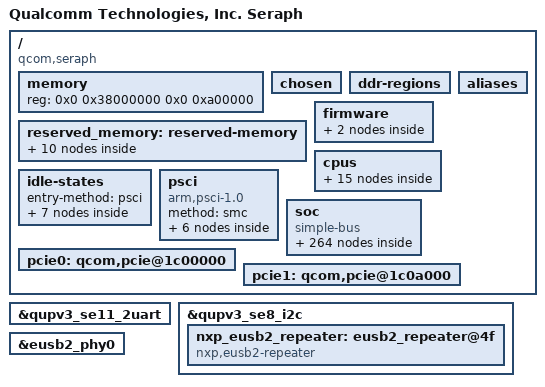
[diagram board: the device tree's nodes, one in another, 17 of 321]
// SPDX-License-Identifier: BSD-3-Clause
/*
 * Copyright (c) Qualcomm Technologies, Inc. and/or its subsidiaries.
 */

#include <dt-bindings/arm/msm/qti-smmu-proxy-dt-ids.h>
#include <dt-bindings/interrupt-controller/arm-gic.h>
#include <dt-bindings/soc/qcom,rpmh-rsc.h>
#include <dt-bindings/clock/qcom,rpmh.h>
#include <dt-bindings/clock/qcom,camcc-seraph.h>
#include <dt-bindings/clock/qcom,evacc-seraph.h>
#include <dt-bindings/clock/qcom,gcc-seraph.h>
#include <dt-bindings/clock/qcom,gpucc-seraph.h>
#include <dt-bindings/clock/qcom,lsrcc-seraph.h>
#include <dt-bindings/clock/qcom,tcsrcc-seraph.h>
#include <dt-bindings/clock/qcom,videocc-seraph.h>
#include <dt-bindings/interconnect/qcom,seraph.h>
#include <dt-bindings/soc/qcom,ipcc.h>
#include <dt-bindings/power/qcom-aoss-qmp.h>
#include <dt-bindings/clock/qcom,aop-qmp.h>
#include <dt-bindings/spmi/spmi.h>
#include <dt-bindings/regulator/qcom,rpmh-regulator-levels.h>
#include <dt-bindings/interrupt-controller/irq.h>
#include <dt-bindings/mailbox/qcom-ipcc.h>

/ {
	model = "Qualcomm Technologies, Inc. Seraph";
	compatible = "qcom,seraph";
	qcom,msm-id = <672 0x10000>;
	interrupt-parent = <&intc>;

	#address-cells = <2>;
	#size-cells = <2>;
	memory { device_type = "memory"; reg = <0x0 0x38000000 0x0 0xa00000>; };

	chosen: chosen {
		bootargs = "loglevel=6 log_buf_len=256K bootconfig swiotlb=0 kasan=off cgroup_disable=pressure cgroup.memory=nokmem,nosocket disable_dma32=on restrict_cma_redirect=false pci=pcie_bus_safe,noaer pcie_pme=nomsi printk.console_no_auto_verbose=1 rcupdate.rcu_expedited=1 rcu_nocbs=0-4 kernel.panic_on_rcu_stall=1 no-steal-acc ftrace_dump_on_oops can.stats_timer=0 fw_devlink.strict=1 service_locator.enable=1 firmware_class.path=/vendor/firmware_mnt/image,/vendor/firmware irqaffinity=0-1 loop.max_part=7 cpufreq.default_governor=performance android_arch_task_struct_size=512 no-steal-acc pci-msm-drv.pcie_sm_regs=0x1D07000,0x1040,0x1048,0x3000,0x2 net.ifnames=0 hibernate.compressor=lz4";
	};

	reserved_memory: reserved-memory {};
	ddr-regions { };

	aliases: aliases {
		serial0 = &qupv3_se11_2uart;
		hsuart0 = &qupv3_se7_4uart;
		hsuart1 = &qupv3_se3_2uart;
		hsuart2 = &qupv3_se1_1uart;
		i2c0 = &qupv3_se0_i2c;
		i2c1 = &qupv3_se1_i2c;
		i2c2 = &qupv3_se2_i2c;
		i2c3 = &qupv3_se3_i2c;
		i2c4 = &qupv3_se4_i2c;
		i2c5 = &qupv3_se5_i2c;
		i2c6 = &qupv3_se6_i2c;
		i2c8 = &qupv3_se8_i2c;
		i2c9 = &qupv3_se9_i2c;
		i2c10 = &qupv3_se10_i2c;
		mmc0 = &sdhc_1;
		spi0 = &qupv3_se0_spi;
		spi1 = &qupv3_se1_spi;
		spi2 = &qupv3_se2_spi;
		spi3 = &qupv3_se3_spi;
		spi4 = &qupv3_se4_spi;
		spi5 = &qupv3_se5_spi;
		spi6 = &qupv3_se6_spi;
		spi8 = &qupv3_se8_spi;
		spi9 = &qupv3_se9_spi;
		spi10 = &qupv3_se10_spi;
	};

	firmware: firmware {
		qcom_scm: qcom_scm { };
	};

	cpus {
		#address-cells = <2>;
		#size-cells = <0>;

		CPU0: cpu@0 {
			device_type = "cpu";
			compatible = "qcom,kryo";
			reg = <0x0 0x0>;
			enable-method = "psci";
			cpu-idle-states = <&SILVER_OFF &SILVER_RAIL_OFF>;
			power-domains = <&CPU_PD0>;
			power-domain-names = "psci";
			next-level-cache = <&L2_0>;
			qcom,freq-domain = <&cpufreq_hw 0>;
			capacity-dmips-mhz = <1024>;
			dynamic-power-coefficient = <100>;
			#cooling-cells = <2>;
			L2_0: l2-cache {
				compatible = "arm,arch-cache";
				cache-level = <2>;
				next-level-cache = <&L3_0>;

				L3_0: l3-cache {
					compatible = "arm,arch-cache";
					cache-level = <3>;
				};
			};
		};

		CPU1: cpu@100 {
			device_type = "cpu";
			compatible = "qcom,kryo";
			reg = <0x0 0x100>;
			enable-method = "psci";
			cpu-idle-states = <&SILVER_OFF &SILVER_RAIL_OFF>;
			power-domains = <&CPU_PD1>;
			power-domain-names = "psci";
			next-level-cache = <&L2_0>;
			qcom,freq-domain = <&cpufreq_hw 0>;
			capacity-dmips-mhz = <1024>;
			dynamic-power-coefficient = <100>;
			#cooling-cells = <2>;
		};

		CPU2: cpu@200 {
			device_type = "cpu";
			compatible = "qcom,kryo";
			reg = <0x0 0x200>;
			enable-method = "psci";
			cpu-idle-states = <&SILVER_OFF &SILVER_RAIL_OFF>;
			power-domains = <&CPU_PD2>;
			power-domain-names = "psci";
			next-level-cache = <&L2_0>;
			qcom,freq-domain = <&cpufreq_hw 0>;
			capacity-dmips-mhz = <1024>;
			dynamic-power-coefficient = <100>;
			#cooling-cells = <2>;
		};

		CPU3: cpu@300 {
			device_type = "cpu";
			compatible = "qcom,kryo";
			reg = <0x0 0x300>;
			enable-method = "psci";
			cpu-idle-states = <&SILVER_OFF &SILVER_RAIL_OFF>;
			power-domains = <&CPU_PD3>;
			power-domain-names = "psci";
			next-level-cache = <&L2_0>;
			qcom,freq-domain = <&cpufreq_hw 0>;
			capacity-dmips-mhz = <1024>;
			dynamic-power-coefficient = <100>;
			#cooling-cells = <2>;
		};

		CPU4: cpu@400 {
			device_type = "cpu";
			compatible = "qcom,kryo";
			reg = <0x0 0x400>;
			enable-method = "psci";
			cpu-idle-states = <&GOLD_OFF &GOLD_RAIL_OFF>;
			power-domains = <&CPU_PD4>;
			power-domain-names = "psci";
			next-level-cache = <&L2_0>;
			qcom,freq-domain = <&cpufreq_hw 1>;
			capacity-dmips-mhz = <1956>;
			dynamic-power-coefficient = <389>;
			#cooling-cells = <2>;
		};

		cpu-map {
			cluster0 {
				core0 {
					cpu = <&CPU0>;
				};

				core1 {
					cpu = <&CPU1>;
				};

				core2 {
					cpu = <&CPU2>;
				};

				core3 {
					cpu = <&CPU3>;
				};
			};

			cluster1 {
				core0 {
					cpu = <&CPU4>;
				};
			};
		};
	};

	idle-states {
		entry-method = "psci";

		SILVER_OFF: silver-c3 {  /* C3 */
			compatible = "arm,idle-state";
			idle-state-name = "pc";
			entry-latency-us = <161>;
			exit-latency-us = <274>;
			min-residency-us = <3200>;
			arm,psci-suspend-param = <0x40000003>;
			local-timer-stop;
		};

		SILVER_RAIL_OFF: silver-cluster0-c4 { /* C4 */
			compatible = "arm,idle-state";
			idle-state-name = "rail-pc";
			entry-latency-us = <292>;
			exit-latency-us = <368>;
			min-residency-us = <6700>;
			arm,psci-suspend-param = <0x40000004>;
			local-timer-stop;
		};

		GOLD_OFF: gold-c3 {  /* C3 */
			compatible = "arm,idle-state";
			idle-state-name = "pc";
			entry-latency-us = <164>;
			exit-latency-us = <457>;
			min-residency-us = <4011>;
			arm,psci-suspend-param = <0x40000003>;
			local-timer-stop;
		};

		GOLD_RAIL_OFF: gold-cluster1-c4 { /* C4 */
			compatible = "arm,idle-state";
			idle-state-name = "rail-pc";
			entry-latency-us = <220>;
			exit-latency-us = <541>;
			min-residency-us = <7951>;
			arm,psci-suspend-param = <0x40000004>;
			local-timer-stop;
		};

		CLUSTER_PWR_DN: cluster-d4 { /* D4 */
			compatible = "domain-idle-state";
			idle-state-name = "l3-off";
			entry-latency-us = <429>;
			exit-latency-us = <1259>;
			min-residency-us = <9144>;
			arm,psci-suspend-param = <0x41000044>;
		};

		CX_OFF: cx-off { /* Cx Off */
			compatible = "domain-idle-state";
			idle-state-name = "cx-ret";
			entry-latency-us = <539>;
			exit-latency-us = <1571>;
			min-residency-us = <8550>;
			arm,psci-suspend-param = <0x41002344>;
		};

		APSS_OFF: cluster-e3 { /* E3 */
			compatible = "domain-idle-state";
			idle-state-name = "llcc-off";
			entry-latency-us = <540>;
			exit-latency-us = <1569>;
			min-residency-us = <10150>;
			arm,psci-suspend-param = <0x4100c344>;
		};
	};

	psci {
		compatible = "arm,psci-1.0";
		method = "smc";

		CPU_PD0: cpu-pd0 {
			#power-domain-cells = <0>;
			power-domains = <&CLUSTER_PD>;
		};

		CPU_PD1: cpu-pd1 {
			#power-domain-cells = <0>;
			power-domains = <&CLUSTER_PD>;
		};

		CPU_PD2: cpu-pd2 {
			#power-domain-cells = <0>;
			power-domains = <&CLUSTER_PD>;
		};

		CPU_PD3: cpu-pd3 {
			#power-domain-cells = <0>;
			power-domains = <&CLUSTER_PD>;
		};

		CPU_PD4: cpu-pd4 {
			#power-domain-cells = <0>;
			power-domains = <&CLUSTER_PD>;
		};

		CLUSTER_PD: cluster-pd {
			#power-domain-cells = <0>;
			domain-idle-states = <&CLUSTER_PWR_DN &CX_OFF &APSS_OFF>;
		};
	};

	soc: soc { };

	pcie0: qcom,pcie@1c00000 { };

	pcie1: qcom,pcie@1c0a000 { };
};

&soc {
	#address-cells = <1>;
	#size-cells = <1>;

	ranges = <0 0 0 0xffffffff>;
	compatible = "simple-bus";

	disp_rdump_region@d5100000 {
	};

	qcom,qrtr-gunyah-tuivm {
		compatible = "qcom,qrtr-gunyah";
		qcom,master;
		gunyah-label = <0x103>;
		peer-name = <2>;
	};

	msm_gpu: qcom,kgsl-3d0@3d00000 { };

	kryo-erp {
		compatible = "arm,arm64-kryo-cpu-erp";
		interrupts = <GIC_PPI 6 IRQ_TYPE_LEVEL_HIGH>,
			     <GIC_SPI 35 IRQ_TYPE_LEVEL_HIGH>;
		interrupt-names = "l1-l2-faultirq","l3-scu-faultirq";
	};

	cluster-device {
		compatible = "qcom,lpm-cluster-dev";
		power-domains = <&CLUSTER_PD>;
	};

	intc: interrupt-controller@17200000 {
		compatible = "arm,gic-v3";
		#interrupt-cells = <3>;
		interrupt-controller;
		ranges;
		#redistributor-regions = <1>;
		redistributor-stride = <0x0 0x20000>;
		reg = <0x17200000 0x10000>,       /* GICD */
		     <0x17260000 0xA0000>;       /* GICR * 5 */
		interrupts = <GIC_PPI 9 IRQ_TYPE_LEVEL_HIGH>;

		gic_its: msi-controller@17240000 {
			compatible = "arm,gic-v3-its";
			msi-controller;
			#msi-cells = <1>;
			reg = <0x17240000 0x20000>;
		};
	};

	arch_timer: timer {
		compatible = "arm,armv8-timer";
		interrupts = <GIC_PPI 13 (GIC_CPU_MASK_SIMPLE(8) | IRQ_TYPE_LEVEL_LOW)>,
			     <GIC_PPI 14 (GIC_CPU_MASK_SIMPLE(8) | IRQ_TYPE_LEVEL_LOW)>,
			     <GIC_PPI 11 (GIC_CPU_MASK_SIMPLE(8) | IRQ_TYPE_LEVEL_LOW)>,
			     <GIC_PPI 12 (GIC_CPU_MASK_SIMPLE(8) | IRQ_TYPE_LEVEL_LOW)>;
		clock-frequency = <19200000>;
	};

	show_resume_irqs@0x17200000 {
		compatible = "qcom,show-resume-irqs";
		reg = <0x17200000 0x110000>;
	};

	ipcc_mproc: qcom,ipcc@404000 {
		compatible = "qcom,ipcc";
		reg = <0x404000 0x1000>;
		interrupts = <GIC_SPI 229 IRQ_TYPE_LEVEL_HIGH>;
		interrupt-controller;
		#interrupt-cells = <3>;
		#mbox-cells = <2>;
	};

	aoss_qmp: power-controller@c300000 {
		compatible = "qcom,aoss-qmp";
		reg = <0xc300000 0x400>;
		interrupt-parent = <&ipcc_mproc>;
		interrupts = <IPCC_CLIENT_AOP
			      IPCC_MPROC_SIGNAL_GLINK_QMP
			      IRQ_TYPE_EDGE_RISING>;
		mboxes = <&ipcc_mproc IPCC_CLIENT_AOP
			  IPCC_MPROC_SIGNAL_GLINK_QMP>;

		#power-domain-cells = <1>;
		#clock-cells = <0>;
	};

	qmp_tme: qcom,qmp-tme {
		compatible = "qcom,qmp-mbox";
		qcom,remote-pid = <14>;
		mboxes = <&ipcc_mproc IPCC_CLIENT_TME
			  IPCC_MPROC_SIGNAL_GLINK_QMP>;
		mbox-names = "tme_qmp";
		interrupt-parent = <&ipcc_mproc>;
		interrupts = <IPCC_CLIENT_TME
			      IPCC_MPROC_SIGNAL_GLINK_QMP
			      IRQ_TYPE_EDGE_RISING>;

		label = "tme";
		qcom,early-boot;
		priority = <0>;
		mbox-desc-offset = <0x0>;
		#mbox-cells = <1>;
	};

	qcom,glink {
		compatible = "qcom,glink";
	};

	qmp_aop: qcom,qmp-aop {
		compatible = "qcom,qmp-mbox";
		qcom,qmp = <&aoss_qmp>;
		label = "aop";
		#mbox-cells = <1>;
	};

	tcsr_mutex_block: syscon@1f40000 {
		compatible = "syscon";
		reg = <0x1f40000 0x20000>;
	};

	tcsr_mutex: hwlock {
		compatible = "qcom,tcsr-mutex";
		syscon = <&tcsr_mutex_block 0 0x1000>;
		#hwlock-cells = <1>;
	};

	tcsr: syscon@1f40000 {
		compatible = "syscon";
		reg = <0x1f40000 0xc0000>;
	};

	qcom,smp2p-adsp {
		compatible = "qcom,smp2p";
		qcom,smem = <443>, <429>;
		interrupt-parent = <&ipcc_mproc>;
		interrupts = <IPCC_CLIENT_LPASS IPCC_MPROC_SIGNAL_SMP2P
			      IRQ_TYPE_EDGE_RISING>;
		mboxes = <&ipcc_mproc IPCC_CLIENT_LPASS
			  IPCC_MPROC_SIGNAL_SMP2P>;
		qcom,local-pid = <0>;
		qcom,remote-pid = <2>;

		adsp_smp2p_out: master-kernel {
			qcom,entry-name = "master-kernel";
			#qcom,smem-state-cells = <1>;
		};

		adsp_smp2p_in: slave-kernel {
			qcom,entry-name = "slave-kernel";
			interrupt-controller;
			#interrupt-cells = <2>;
		};

		sleepstate_smp2p_out: sleepstate-out {
			qcom,entry-name = "sleepstate";
			#qcom,smem-state-cells = <1>;
		};

		sleepstate_smp2p_in: qcom,sleepstate-in {
			qcom,entry-name = "sleepstate_see";
			interrupt-controller;
			#interrupt-cells = <2>;
		};

		smp2p_rdbg2_out: qcom,smp2p-rdbg2-out {
			qcom,entry-name = "rdbg";
			#qcom,smem-state-cells = <1>;
		};

		smp2p_rdbg2_in: qcom,smp2p-rdbg2-in {
			qcom,entry-name = "rdbg";
			interrupt-controller;
			#interrupt-cells = <2>;
		};
	};

	qcom,smp2p-cdsp {
		compatible = "qcom,smp2p";
		qcom,smem = <94>, <432>;
		interrupt-parent = <&ipcc_mproc>;
		interrupts = <IPCC_CLIENT_CDSP IPCC_MPROC_SIGNAL_SMP2P
			      IRQ_TYPE_EDGE_RISING>;
		mboxes = <&ipcc_mproc IPCC_CLIENT_CDSP IPCC_MPROC_SIGNAL_SMP2P>;
		qcom,local-pid = <0>;
		qcom,remote-pid = <5>;

		cdsp_smp2p_out: master-kernel {
			qcom,entry-name = "master-kernel";
			#qcom,smem-state-cells = <1>;
		};

		cdsp_smp2p_in: slave-kernel {
			qcom,entry-name = "slave-kernel";
			interrupt-controller;
			#interrupt-cells = <2>;
		};

		smp2p_rdbg5_out: qcom,smp2p-rdbg5-out {
			qcom,entry-name = "rdbg";
			#qcom,smem-state-cells = <1>;
		};

		smp2p_rdbg5_in: qcom,smp2p-rdbg5-in {
			qcom,entry-name = "rdbg";
			interrupt-controller;
			#interrupt-cells = <2>;
		};
	};

	qcom,smp2p-soccp {
		compatible = "qcom,smp2p";
		qcom,smem = <617>, <616>;
		interrupt-parent = <&ipcc_mproc>;
		interrupts = <IPCC_CLIENT_SOCCP IPCC_MPROC_SIGNAL_SMP2P
			      IRQ_TYPE_EDGE_RISING>;
		mboxes = <&ipcc_mproc IPCC_CLIENT_SOCCP IPCC_MPROC_SIGNAL_SMP2P>;
		qcom,local-pid = <0>;
		qcom,remote-pid = <19>;

		soccp_smp2p_out: master-kernel {
			qcom,entry-name = "master-kernel";
			#qcom,smem-state-cells = <1>;
		};

		soccp_smp2p_in: slave-kernel {
			qcom,entry-name = "slave-kernel";
			interrupt-controller;
			#interrupt-cells = <2>;
		};
	};

	qcom_smp2p_dcp: qcom,smp2p-dcp {
		compatible = "qcom,smp2p";
		qcom,smem = <617>, <616>;
		interrupt-parent = <&ipcc_mproc>;
		interrupts = <IPCC_CLIENT_DCP IPCC_MPROC_SIGNAL_SMP2P
			      IRQ_TYPE_EDGE_RISING>;
		mboxes = <&ipcc_mproc IPCC_CLIENT_DCP IPCC_MPROC_SIGNAL_SMP2P>;
		qcom,local-pid = <0>;
		qcom,remote-pid = <22>;

		dcp_smp2p_out: master-kernel {
			qcom,entry-name = "master-kernel";
			#qcom,smem-state-cells = <1>;
		};

		dcp_smp2p_in: slave-kernel {
			qcom,entry-name = "slave-kernel";
			interrupt-controller;
			#interrupt-cells = <2>;
		};
	};

	qcom,smp2p_sleepstate {
		compatible = "qcom,smp2p-sleepstate";
		qcom,smem-states = <&sleepstate_smp2p_out 0>;
		interrupt-parent = <&sleepstate_smp2p_in>;
		interrupts = <0 0>;
		interrupt-names = "smp2p-sleepstate-in";
	};

	qcom,glinkpkt {
		compatible = "qcom,glinkpkt";

		qcom,glinkpkt-at-mdm0 {
			qcom,glinkpkt-edge = "mpss";
			qcom,glinkpkt-ch-name = "DS";
			qcom,glinkpkt-dev-name = "at_mdm0";
		};

		qcom,glinkpkt-ctrl-cdsp {
			qcom,glinkpkt-edge = "cdsp";
			qcom,glinkpkt-ch-name = "LOOPBACK_CTL_CDSP";
			qcom,glinkpkt-dev-name = "glink_pkt_ctrl_cdsp";
		};

		qcom,glinkpkt-data-cdsp {
			qcom,glinkpkt-edge = "cdsp";
			qcom,glinkpkt-ch-name = "LOOPBACK_DATA_CDSP";
			qcom,glinkpkt-dev-name = "glink_pkt_data_cdsp";
		};

		qcom,glinkpkt-ctrl-lpass {
			qcom,glinkpkt-edge = "lpass";
			qcom,glinkpkt-ch-name = "LOOPBACK_CTL_LPASS";
			qcom,glinkpkt-dev-name = "glink_pkt_ctrl_lpass";
		};

		qcom,glinkpkt-data-lpass {
			qcom,glinkpkt-edge = "lpass";
			qcom,glinkpkt-ch-name = "LOOPBACK_DATA_LPASS";
			qcom,glinkpkt-dev-name = "glink_pkt_data_lpass";
		};

		qcom,glinkpkt-ctrl-mpss {
			qcom,glinkpkt-edge = "mpss";
			qcom,glinkpkt-ch-name = "LOOPBACK_CTL_MPSS";
			qcom,glinkpkt-dev-name = "glink_pkt_ctrl_mpss";
		};

		qcom,glinkpkt-data-mpss {
			qcom,glinkpkt-edge = "mpss";
			qcom,glinkpkt-ch-name = "LOOPBACK_DATA_MPSS";
			qcom,glinkpkt-dev-name = "glink_pkt_data_mpss";
		};

		qcom,glinkpkt-apr-apps2 {
			qcom,glinkpkt-edge = "adsp";
			qcom,glinkpkt-ch-name = "apr_apps2";
			qcom,glinkpkt-dev-name = "apr_apps2";
		};

		qcom,glinkpkt-data40-cntl {
			qcom,glinkpkt-edge = "mpss";
			qcom,glinkpkt-ch-name = "DATA40_CNTL";
			qcom,glinkpkt-dev-name = "smdcntl8";
		};

		qcom,glinkpkt-data1 {
			qcom,glinkpkt-edge = "mpss";
			qcom,glinkpkt-ch-name = "DATA1";
			qcom,glinkpkt-dev-name = "smd7";
		};

		qcom,glinkpkt-data4 {
			qcom,glinkpkt-edge = "mpss";
			qcom,glinkpkt-ch-name = "DATA4";
			qcom,glinkpkt-dev-name = "smd8";
		};

		qcom,glinkpkt-data11 {
			qcom,glinkpkt-edge = "mpss";
			qcom,glinkpkt-ch-name = "DATA11";
			qcom,glinkpkt-dev-name = "smd11";
		};

		qcom,glinkpkt-qmc-dma {
			qcom,glinkpkt-edge = "mpss";
			qcom,glinkpkt-ch-name = "QMC_DMA_LINE";
			qcom,glinkpkt-dev-name = "qmc_dma";
			qcom,glinkpkt-enable-ch-close;
		};

		qcom,glinkpkt-qmc-cma {
			qcom,glinkpkt-edge = "mpss";
			qcom,glinkpkt-ch-name = "QMC_CMA_LINE";
			qcom,glinkpkt-dev-name = "qmc_cma";
			qcom,glinkpkt-enable-ch-close;
		};

		qcom,glinkpkt-ims-sub-1 {
			qcom,glinkpkt-edge = "mpss";
			qcom,glinkpkt-ch-name = "Ims_dc_sub1";
			qcom,glinkpkt-dev-name = "ims_dc_sub1";
			qcom,glinkpkt-enable-ch-close;
		};

		qcom,glinkpkt-ims-sub-2 {
			qcom,glinkpkt-edge = "mpss";
			qcom,glinkpkt-ch-name = "Ims_dc_sub2";
			qcom,glinkpkt-dev-name = "ims_dc_sub2";
			qcom,glinkpkt-enable-ch-close;
		};

		qcom,glinkpkt-xpan_control {
			qcom,glinkpkt-edge = "adsp";
			qcom,glinkpkt-ch-name = "bt_cp_ctrl";
			qcom,glinkpkt-dev-name = "bt_cp_ctrl";
		};

		qcom,glinkpkt-hci-aribter {
			qcom,glinkpkt-edge = "lpass";
			qcom,glinkpkt-ch-name = "hci_arbiter_chnl";
			qcom,glinkpkt-dev-name = "glink_pkt_hci_arbiter_chnl";
			qcom,glinkpkt-enable-ch-close;
		};

		qcom,glinkpkt-socket-offload {
			qcom,glinkpkt-edge = "lpass";
			qcom,glinkpkt-ch-name = "bt_socket_hal_chnl";
			qcom,glinkpkt-dev-name = "glink_pkt_bt_socket_hal_chnl";
			qcom,glinkpkt-enable-ch-close;
		};

		qcom,glinkpkt-gatt-offload {
			qcom,glinkpkt-edge = "lpass";
			qcom,glinkpkt-ch-name = "gatt_offload_chnl";
			qcom,glinkpkt-dev-name = "glink_pkt_bt_gatt_offload_chnl";
			qcom,glinkpkt-enable-ch-close;
		};
	};

	memtimer: timer@17420000 {
		#address-cells = <1>;
		#size-cells = <1>;
		ranges;
		compatible = "arm,armv7-timer-mem";
		reg = <0x17420000 0x1000>;
		clock-frequency = <19200000>;

		frame@17421000 {
			frame-number = <0>;
			interrupts = <GIC_SPI 8 IRQ_TYPE_LEVEL_HIGH>,
				     <GIC_SPI 6 IRQ_TYPE_LEVEL_HIGH>;
			reg = <0x17421000 0x1000>,
			      <0x17422000 0x1000>;
		};

		frame@17423000 {
			frame-number = <1>;
			interrupts = <GIC_SPI 9 IRQ_TYPE_LEVEL_HIGH>;
			reg = <0x17423000 0x1000>;
			status = "disabled";
		};

		frame@17425000 {
			frame-number = <2>;
			interrupts = <GIC_SPI 10 IRQ_TYPE_LEVEL_HIGH>;
			reg = <0x17425000 0x1000>;
			status = "disabled";
		};

		frame@17427000 {
			frame-number = <3>;
			interrupts = <GIC_SPI 11 IRQ_TYPE_LEVEL_HIGH>;
			reg = <0x17427000 0x1000>;
			status = "disabled";
		};

		frame@17429000 {
			frame-number = <4>;
			interrupts = <GIC_SPI 12 IRQ_TYPE_LEVEL_HIGH>;
			reg = <0x17429000 0x1000>;
			status = "disabled";
		};

		frame@1742b000 {
			frame-number = <5>;
			interrupts = <GIC_SPI 13 IRQ_TYPE_LEVEL_HIGH>;
			reg = <0x1742b000 0x1000>;
			status = "disabled";
		};

		frame@1742d000 {
			frame-number = <6>;
			interrupts = <GIC_SPI 14 IRQ_TYPE_LEVEL_HIGH>;
			reg = <0x1742d000 0x1000>;
			status = "disabled";
		};
	};

	cnss_ipa_wlan_iommu_group0: cnss_ipa_wlan_iommu_group0 {
		qcom,iommu-msi-size = <0x1000>;
		qcom,iommu-geometry = <0x98000000 0x18010000>;
		qcom,iommu-dma = "fastmap";
		qcom,iommu-pagetable = "coherent";
		qcom,iommu-faults = "stall-disable", "HUPCF",
					"non-fatal";
	};

	dload_mode {
		compatible = "qcom,dload-mode";
		mmcx-supply = <&VDD_MMCX_LEVEL>;
		mmcx-uV-uA = <RPMH_REGULATOR_LEVEL_TURBO 0>;
		reg-names = "mmcx";
	};

	apps_rsc: rsc@17a00000 {
		label = "apps_rsc";
		compatible = "qcom,rpmh-rsc";
		reg = <0x17a00000 0x10000>,
		      <0x17a10000 0x10000>,
		      <0x17a20000 0x10000>;
		reg-names = "drv-0", "drv-1", "drv-2";
		qcom,drv-count = <3>;
		interrupts = <GIC_SPI 3 IRQ_TYPE_LEVEL_HIGH>,
			     <GIC_SPI 4 IRQ_TYPE_LEVEL_HIGH>,
			     <GIC_SPI 5 IRQ_TYPE_LEVEL_HIGH>;
		power-domains = <&CLUSTER_PD>;

		apps_rsc_drv2: drv@2 {
			qcom,drv-id = <2>;
			qcom,tcs-offset = <0xd00>;
			qcom,tcs-distance = <0x2a0>;
			channel@0 {
				qcom,tcs-config = <ACTIVE_TCS    3>,
						  <SLEEP_TCS     2>,
						  <WAKE_TCS      2>,
						  <CONTROL_TCS   0>,
						  <FAST_PATH_TCS 1>;
			};

			apps_bcm_voter: bcm_voter {
				compatible = "qcom,bcm-voter";
			};

			dcvs_fp: qcom,dcvs-fp {
				compatible = "qcom,dcvs-fp";
				qcom,ddr-bcm-name = "MC3";
				qcom,llcc-bcm-name = "SH3";

			};

			rpmhcc: clock-controller {
				compatible = "qcom,seraph-rpmh-clk";
				#clock-cells = <1>;
			};
		};
	};

	mmio_sram: mmio-sram@1901E100 {
		#address-cells = <1>;
		#size-cells = <1>;
		compatible = "mmio-sram";
		reg = <0x1901E100 0x200>;
		ranges = <0x0 0x1901E100 0x200>;

		cpu_scp_lpri: scmi-shmem@0 {
			compatible = "arm,scmi-shmem";
			reg = <0x0 0x200>;
		};
	};

	cpucp: qcom,cpucp@17400000 {
		compatible = "qcom,cpucp";
		reg =   <0x17400000 0x10>,
			<0x17d90000 0x3000>;
		reg-names = "tx", "rx";
		#mbox-cells = <1>;
		interrupts = <GIC_SPI 60 IRQ_TYPE_LEVEL_HIGH>;
	};

	scmi: qcom,scmi {
		#address-cells = <1>;
		#size-cells = <0>;
		compatible = "arm,scmi";
		mboxes = <&cpucp 0>;
		mbox-names = "tx";
		shmem = <&cpu_scp_lpri>;

		scmi_qcom: protocol@80 {
			reg = <0x80>;
			#clock-cells = <1>;
		};
	};

	qcom_cpufreq_stats: qcom,cpufreq_stats {
		compatible = "qcom,cpufreq-stats-v2";
	};

	cpucp_log: qcom,cpucp_log@d8050000 {
		compatible = "qcom,cpucp-log";
		reg = <0xD8040000 0x10000>, <0xD8050000 0x10000>;
		mboxes = <&cpucp 1>;
		qcom,log-type = <0>;
	};

	qti,smmu-proxy {
		compatible = "smmu-proxy-sender";
	};

	qcom,seccamtest {
		compatible = "qcom,seccamtest";
		qti,smmu-proxy-cb-id = <QTI_SMMU_PROXY_CAMERA_CB>;
	};

	llcc_pmu: llcc-pmu@24095000 {
		compatible = "qcom,llcc-pmu-ver2";
		reg = <0x24095000 0x300>;
		reg-names = "lagg-base";
	};

	qcom_pmu: qcom,pmu {
		compatible = "qcom,pmu";
		qcom,pmu-events-tbl =
			< 0x0008 0x3F 0xFF 0xFF >,
			< 0x0011 0x3F 0xFF 0xFF >,
			< 0x0017 0x3F 0xFF 0xFF >,
			< 0x002A 0x3F 0xFF 0xFF >,
			< 0x1000 0x3F 0xFF 0xFF >;
	};

	ddr_freq_table: ddr-freq-table {
		qcom,freq-tbl =
			<  451200 >,
			<  547200 >,
			< 1353600 >,
			< 1555200 >,
			< 1708800 >,
			< 2092800 >,
			< 2736000 >,
			< 3187200 >,
			< 3686400 >,
			< 4224000 >;
	};

	llcc_freq_table: llcc-freq-table {
		qcom,freq-tbl =
			< 250000 >,
			< 350000 >,
			< 533000 >,
			< 600000 >,
			< 710670 >,
			< 806000 >,
			< 933000 >;
	};

	ddrqos_freq_table: ddrqos-freq-table {
		qcom,freq-tbl =
		< 0 >,
		< 1 >;
	};

	qcom_dcvs_prof: qcom-dcvs-prof {
		max_masters = <4>;
	};

	qcom_dcvs: qcom,dcvs {
		compatible = "qcom,dcvs";
		#address-cells = <1>;
		#size-cells = <1>;
		ranges;

		qcom_l3_dcvs_hw: l3 {
			compatible = "qcom,dcvs-hw";
			qcom,dcvs-hw-type = <2>;
			qcom,bus-width = <32>;
			reg = <0x17d90000 0x4000>, <0x17d90100 0xa0>;
			reg-names = "l3-base", "l3tbl-base";

			l3_dcvs_sp: sp {
				compatible = "qcom,dcvs-path";
				qcom,dcvs-path-type = <0>;
				qcom,shared-offset = <0x0090>;
			};
		};

		qcom_ddr_dcvs_hw: ddr {
			compatible = "qcom,dcvs-hw";
			qcom,dcvs-hw-type = <0>;
			qcom,bus-width = <4>;
			qcom,freq-tbl = <&ddr_freq_table>;

			ddr_dcvs_sp: sp {
				compatible = "qcom,dcvs-path";
				qcom,dcvs-path-type = <0>;
				interconnects = <&mc_virt MASTER_LLCC
						 &mc_virt SLAVE_EBI1>;
			};

			ddr_dcvs_fp: fp {
				compatible = "qcom,dcvs-path";
				qcom,dcvs-path-type = <1>;
				qcom,fp-voter = <&dcvs_fp>;
			};

		};

		qcom_llcc_dcvs_hw: llcc {
			compatible = "qcom,dcvs-hw";
			qcom,dcvs-hw-type = <1>;
			qcom,bus-width = <16>;
			qcom,freq-tbl = <&llcc_freq_table>;

			llcc_dcvs_sp: sp {
				compatible = "qcom,dcvs-path";
				qcom,dcvs-path-type = <0>;
				interconnects = <&gem_noc MASTER_APPSS_PROC
						 &gem_noc SLAVE_LLCC>;
			};

			llcc_dcvs_fp: fp {
				compatible = "qcom,dcvs-path";
				qcom,dcvs-path-type = <1>;
				qcom,fp-voter = <&dcvs_fp>;
			};

		};

		qcom_ddrqos_dcvs_hw: ddrqos {
			compatible = "qcom,dcvs-hw";
			qcom,dcvs-hw-type = <3>;
			qcom,bus-width = <1>;
			qcom,freq-tbl = <&ddrqos_freq_table>;

			ddrqos_dcvs_sp: sp {
				compatible = "qcom,dcvs-path";
				qcom,dcvs-path-type = <0>;
				interconnects = <&mc_virt MASTER_LLCC
					 &mc_virt SLAVE_EBI1>;
			};
		};
	};

	qcom_memlat: qcom,memlat {
		compatible = "qcom,memlat";
		ddr {
			compatible = "qcom,memlat-grp";
			qcom,target-dev = <&qcom_ddr_dcvs_hw>;
			qcom,sampling-path = <&ddr_dcvs_fp>;
			qcom,miss-ev = <0x1000>;

			silver {
				compatible = "qcom,memlat-mon";
				qcom,cpulist = <&CPU0 &CPU1 &CPU2 &CPU3>;
				qcom,cpufreq-memfreq-tbl =
					<  691200  451200 >,
					<  960000  547200 >,
					< 1113600 1353600 >,
					< 1248000 1708800 >,
					< 1440000 2092800 >,
					< 1555200 2736000 >,
					< 1689600 3187200 >,
					< 1804800 3686400 >,
					< 1996800 4224000 >;
				qcom,sampling-enabled;
			};

			gold {
				compatible = "qcom,memlat-mon";
				qcom,cpulist = <&CPU4>;
				qcom,sampling-enabled;
				qcom,cpufreq-memfreq-tbl =
					<  672000  451200 >,
					<  960000  547200 >,
					< 1248000 1353600 >,
					< 1363200 1708800 >,
					< 1497600 2092800 >,
					< 1612800 2736000 >,
					< 1728000 3187200 >,
					< 1881600 3686400 >,
					< 2035200 4224000 >;
			};

			silver-compute {
				compatible = "qcom,memlat-mon";
				qcom,cpulist = <&CPU0 &CPU1 &CPU2 &CPU3>;
				qcom,sampling-enabled;
				qcom,compute-mon;
				qcom,cpufreq-memfreq-tbl =
					< 1689600  451200 >,
					< 1996800 4224000 >;
			};

			gold-compute {
				compatible = "qcom,memlat-mon";
				qcom,cpulist = <&CPU4>;
				qcom,sampling-enabled;
				qcom,compute-mon;
				qcom,cpufreq-memfreq-tbl =
					< 1728000  451200 >,
					< 2035200 4224000 >;
			};
		};

		llcc {
			compatible = "qcom,memlat-grp";
			qcom,target-dev = <&qcom_llcc_dcvs_hw>;
			qcom,sampling-path = <&llcc_dcvs_fp>;
			qcom,miss-ev = <0x2A>;

			silver {
				compatible = "qcom,memlat-mon";
				qcom,cpulist = <&CPU0 &CPU1 &CPU2 &CPU3>;
				qcom,cpufreq-memfreq-tbl =
					<  691200 250000 >,
					<  960000 350000 >,
					< 1113600 533000 >,
					< 1440000 600000 >,
					< 1555200 710670 >,
					< 1689600 806000 >,
					< 1996800 933000 >;
				qcom,sampling-enabled;
			};

			gold {
				compatible = "qcom,memlat-mon";
				qcom,cpulist = <&CPU4>;
				qcom,cpufreq-memfreq-tbl =
					<  672000 250000 >,
					<  960000 350000 >,
					< 1248000 533000 >,
					< 1363200 600000 >,
					< 1612800 710670 >,
					< 1728000 806000 >,
					< 2035200 933000 >;
				qcom,sampling-enabled;
			};

			silver-compute {
				compatible = "qcom,memlat-mon";
				qcom,cpulist = <&CPU0 &CPU1 &CPU2 &CPU3>;
				qcom,cpufreq-memfreq-tbl =
					< 1689600 250000 >,
					< 1996800 933000 >;
				qcom,sampling-enabled;
				qcom,compute-mon;
			};

			gold-compute {
				compatible = "qcom,memlat-mon";
				qcom,cpulist = <&CPU4>;
				qcom,cpufreq-memfreq-tbl =
					< 1728000 250000 >,
					< 2035200 933000 >;
				qcom,sampling-enabled;
				qcom,compute-mon;
			};
		};

		l3 {
			compatible = "qcom,memlat-grp";
			qcom,target-dev = <&qcom_l3_dcvs_hw>;
			qcom,sampling-path = <&l3_dcvs_sp>;
			qcom,miss-ev = <0x17>;

			silver {
				compatible = "qcom,memlat-mon";
				qcom,cpulist = <&CPU0 &CPU1 &CPU2 &CPU3>;
				qcom,cpufreq-memfreq-tbl =
					<  268800  268800 >,
					<  518400  403200 >,
					<  691200  556800 >,
					<  960000  806400 >,
					< 1113600  902400 >,
					< 1248000 1113600 >,
					< 1440000 1209600 >,
					< 1555200 1363200 >,
					< 1689600 1401600 >,
					< 1804800 1516800 >,
					< 1996800 1612800 >;
				qcom,sampling-enabled;
			};

			gold {
				compatible = "qcom,memlat-mon";
				qcom,cpulist = <&CPU4>;
				qcom,cpufreq-memfreq-tbl =
					<  268800  268800 >,
					<  518400  403200 >,
					<  672000  556800 >,
					<  960000  806400 >,
					< 1248000  902400 >,
					< 1363200 1113600 >,
					< 1497600 1209600 >,
					< 1612800 1363200 >,
					< 1728000 1401600 >,
					< 1881600 1516800 >,
					< 2035200 1612800 >;
				qcom,sampling-enabled;
			};

			silver-compute {
				compatible = "qcom,memlat-mon";
				qcom,cpulist = <&CPU0 &CPU1 &CPU2 &CPU3>;
				qcom,cpufreq-memfreq-tbl =
					< 1689600  268800 >,
					< 1996800 1612800 >;
				qcom,sampling-enabled;
				qcom,compute-mon;
			};

			gold-compute {
				compatible = "qcom,memlat-mon";
				qcom,cpulist = <&CPU4>;
				qcom,cpufreq-memfreq-tbl =
					< 1728000  268800 >,
					< 2035200 1612800 >;
				qcom,sampling-enabled;
				qcom,compute-mon;
			};
		};

		ddrqos {
			compatible = "qcom,memlat-grp";
			qcom,target-dev = <&qcom_ddrqos_dcvs_hw>;
			qcom,sampling-path = <&ddrqos_dcvs_sp>;
			qcom,miss-ev = <0x1000>;

			ddrqos_gold_latfloor: gold-latfloor {
				compatible = "qcom,memlat-mon";
				qcom,cpulist = <&CPU0 &CPU1 &CPU2 &CPU3 &CPU4>;
				qcom,cpufreq-memfreq-tbl =
					< 1728000 0 >,
					< 2035200 1 >;
				qcom,sampling-enabled;
			};
		};
	};

	bwmon_llcc: qcom,bwmon-llcc@240B5300 {
		compatible = "qcom,bwmon4";
		reg = <0x240B5400 0x300>, <0x240B5300 0x200>;
		reg-names = "base", "global_base";
		interrupts = <GIC_SPI 581 IRQ_TYPE_LEVEL_HIGH>;
		qcom,mport = <0>;
		qcom,hw-timer-hz = <19200000>;
		qcom,count-unit = <0x10000>;
		qcom,target-dev = <&qcom_llcc_dcvs_hw>;
	};

	bwmon_ddr: qcom,bwmon-ddr@24091000 {
		compatible = "qcom,bwmon5";
		reg = <0x24091000 0x1000>;
		reg-names = "base";
		interrupts = <GIC_SPI 81 IRQ_TYPE_LEVEL_HIGH>;
		qcom,hw-timer-hz = <19200000>;
		qcom,count-unit = <0x10000>;
		qcom,target-dev = <&qcom_ddr_dcvs_hw>;
	};

	bwprof_scmi: qcom,bwprof-scmi {
		compatible = "qcom,bwprof-scmi";
		#address-cells = <1>;
		#size-cells = <1>;
		ranges;
		reg = <0x1901C000 0x1000>;
		reg-names = "mem-base";
		mboxes = <&cpucp 2>;

		bwprof_ddr: ddr {
			compatible = "qcom,bwprof-hw";
			qcom,hw-type = < 0 >;
			qcom,bus_width = < 4 >;

			bwprof_ddr_1ms: 1ms {
				compatible = "qcom,bwprof-sampling-mode";
				qcom,sample-period = < 1 >;
				qcom,master-list = /bits/ 8 < 50 51 >;
			};

			bwprof_ddr_10ms: 10ms {
				compatible = "qcom,bwprof-sampling-mode";
				qcom,sample-period = < 10 >;
				qcom,master-list = /bits/ 8 < 50 51 53 54 55 56 57 >;
			};

			bwprof_ddr_100ms: 100ms {
				compatible = "qcom,bwprof-sampling-mode";
				qcom,sample-period = < 100 >;
				qcom,master-list = /bits/ 8 < 50 51 52 53 54 55 56 57 >;
			};

			bwprof_ddr_hist: Hist {
				compatible = "qcom,bwprof-sampling-mode";
				qcom,sample-period = < 1 >;
				qcom,master-list = /bits/ 8 < 50 51 52 >;
				qcom,hist-enable;
			};
		};

		bwprof_llcc: llcc {
			compatible = "qcom,bwprof-hw";
			qcom,hw-type = < 1 >;
			qcom,bus_width = < 32 >;

			bwprof_llcc_1ms: 1ms {
				compatible = "qcom,bwprof-sampling-mode";
				qcom,sample-period = < 1 >;
				qcom,master-list = /bits/ 8 < 0 1 >;
			};

			bwprof_llcc_10ms: 10ms {
				compatible = "qcom,bwprof-sampling-mode";
				qcom,sample-period = < 10 >;
				qcom,master-list = /bits/ 8 < 0 1 3 4 5 6 7 >;
			};

			bwprof_llcc_100ms: 100ms {
				compatible = "qcom,bwprof-sampling-mode";
				qcom,sample-period = < 100 >;
				qcom,master-list = /bits/ 8 < 0 1 2 3 4 5 6 7 >;
			};

			bwprof_llcc_hist: Hist {
				compatible = "qcom,bwprof-sampling-mode";
				qcom,sample-period = < 1 >;
				qcom,master-list = /bits/ 8 < 0 1 2 >;
				qcom,hist-enable;
			};
		};
	};

	pdc: interrupt-controller@b220000 {
		compatible = "qcom,seraph-pdc", "qcom,pdc";
		reg = <0xb220000 0x10000>, <0x174000f0 0x64>;
		qcom,pdc-ranges = <0 221 1>, <1 227 2>, <3 238 4>,
				  <8 263 2>, <10 293 3>, <14 297 2>,
				  <16 348 2>, <18 351 3>, <22 355 2>,
				  <24 641 1>, <25 358 1>, <26 376 2>,
				  <28 443 1>, <30 242 1>, <31 296 1>,
				  <32 354 1>, <33 357 1>, <34 444 3>,
				  <37 472 1>, <40 447 1>, <41 461 1>,
				  <42 473 1>, <43 462 1>, <44 584 1>,
				  <45 586 1>, <47 607 2>, <49 642 1>,
				  <50 656 1>, <51 527 1>, <61 505 1>,
				  <62 605 1>, <63 372 2>, <65 378 1>,
				  <66 431 1>, <70 528 46>, <116 609 31>,
				  <147 63 1>, <148 716 12>, <160 251 5>,
				  <165 379 1>;
		#interrupt-cells = <2>;
		interrupt-parent = <&intc>;
		interrupt-controller;
	};

	sys-pm-vx@c320000 {
		compatible = "qcom,sys-pm-violators", "qcom,sys-pm-seraph";
		reg = <0xc320000 0x400>;
		qcom,qmp = <&aoss_qmp>;
	};

	cpuss-sleep-stats@17800054 {
		compatible = "qcom,cpuss-sleep-stats-v4";
		reg = <0x17800054 0x4>, <0x17810054 0x4>, <0x17820054 0x4>,
		      <0x17830054 0x4>, <0x17840054 0x4>, <0x17880098 0x4>,
		      <0x178c0000 0x10000>;
		reg-names = "seq_lpm_cntr_cfg_cpu0", "seq_lpm_cntr_cfg_cpu1",
			    "seq_lpm_cntr_cfg_cpu2", "seq_lpm_cntr_cfg_cpu3",
			    "seq_lpm_cntr_cfg_cpu4", "l3_seq_lpm_cntr_cfg",
			    "apss_seq_mem_base";
		num-cpus = <5>;
	};

	sram@c3f0000 {
		compatible = "qcom,rpmh-stats-v4";
		reg = <0xc3f0000 0x400>;
		qcom,qmp = <&aoss_qmp>;
		ss-name = "modem", "wpss", "adsp", "adsp_island",
			  "cdsp", "apss";
	};

	pcie_crm: crm@1d01000 {
		label = "pcie_crm";
		compatible = "qcom,pcie-crm-v2";
		reg = <0x1d01000 0x2000>, <0x1d03000 0x400>, <0x1d03400 0x400>,
		      <0x1d03800 0x2000>, <0x1d05800 0x700>, <0x1d05f00 0x100>;
		reg-names = "base", "crm_b", "crm_b_pt", "crm_c", "crm_v", "common";
		interrupts = <GIC_SPI 501 IRQ_TYPE_EDGE_RISING>;
		interrupt-names = "pcie_crm_drv0";
		clocks = <&pcie_0_pipe_clk>;
		qcom,hw-drv-ids = <0 1>;
		qcom,sw-drv-ids = <0>;
	};

	pcie_pdc: pdc@b310000 {
		compatible = "qcom,seraph-pcie-pdc", "qcom,pcie-pdc";
		reg = <0xb310000 0x20000>;
	};

	clocks {
		xo_board: xo_board {
			compatible = "fixed-clock";
			clock-frequency = <38400000>;
			clock-output-names = "xo_board";
			#clock-cells = <0>;
		};

		sleep_clk: sleep_clk {
			compatible = "fixed-clock";
			clock-frequency = <32000>;
			clock-output-names = "sleep_clk";
			#clock-cells = <0>;
		};

		pcie_0_pipe_clk: pcie_0_pipe_clk {
			compatible = "fixed-clock";
			clock-frequency = <1000>;
			clock-output-names = "pcie_0_pipe_clk";
			#clock-cells = <0>;
		};

		pcie_1_pipe_clk: pcie_1_pipe_clk {
			compatible = "fixed-clock";
			clock-frequency = <1000>;
			clock-output-names = "pcie_1_pipe_clk";
			#clock-cells = <0>;
		};

		usb3_phy_wrapper_gcc_usb30_pipe_clk: usb3_phy_wrapper_gcc_usb30_pipe_clk {
			compatible = "fixed-clock";
			clock-frequency = <1000>;
			clock-output-names = "usb3_phy_wrapper_gcc_usb30_pipe_clk";
			#clock-cells = <0>;
		};
	};

	camcc: clock-controller@ade0000 {
		compatible = "qcom,seraph-camcc", "syscon";
		reg = <0xade0000 0x20000>;
		reg-name = "cc_base";
		vdd_cx-supply = <&VDD_CX_LEVEL>;
		vdd_mx-supply = <&VDD_MX_LEVEL>;
		clocks = <&rpmhcc RPMH_CXO_CLK>,
			 <&sleep_clk>, <&gcc GCC_CAMERA_AHB_CLK>;
		clock-names = "bi_tcxo",
			      "sleep_clk", "iface";
		interconnects = <&mmss_noc MASTER_CAMNOC_HF &mc_virt SLAVE_EBI1>;
		interconnect-names = "cam-to-ddr";
		#clock-cells = <1>;
		#reset-cells = <1>;
		#power-domain-cells = <1>;
	};

	evacc: clock-controller@a8f0000 {
		compatible = "qcom,seraph-evacc", "syscon";
		reg = <0xa8f0000 0x10000>;
		reg-name = "cc_base";
		vdd_mm-supply = <&VDD_MM_LEVEL>;
		vdd_mx-supply = <&VDD_MX_LEVEL>;
		clocks = <&rpmhcc RPMH_CXO_CLK>,
			 <&sleep_clk>, <&gcc GCC_EVA_AHB_CLK>;
		clock-names = "bi_tcxo",
			      "sleep_clk", "iface";
		#clock-cells = <1>;
		#reset-cells = <1>;
		#power-domain-cells = <1>;
	};

	gcc: clock-controller@100000 {
		compatible = "qcom,seraph-gcc", "syscon";
		reg = <0x100000 0x1f4200>;
		reg-name = "cc_base";
		vdd_cx-supply = <&VDD_CX_LEVEL>;
		vdd_mx-supply = <&VDD_MX_LEVEL>;
		clocks = <&rpmhcc RPMH_CXO_CLK>,
			 <&pcie_0_pipe_clk>,
			 <&pcie_1_pipe_clk>,
			 <&sleep_clk>,
			 <&usb3_phy_wrapper_gcc_usb30_pipe_clk>;
		clock-names = "bi_tcxo",
			      "pcie_0_pipe_clk",
			      "pcie_1_pipe_clk",
			      "sleep_clk",
			      "usb3_phy_wrapper_gcc_usb30_pipe_clk";
		#clock-cells = <1>;
		#reset-cells = <1>;
		#power-domain-cells = <1>;
	};

	gpucc: clock-controller@3d90000 {
		compatible = "qcom,seraph-gpucc", "syscon";
		reg = <0x3d90000 0x9800>;
		reg-name = "cc_base";
		vdd_cx-supply = <&VDD_CX_LEVEL>;
		vdd_mx-supply = <&VDD_MX_LEVEL>;
		clocks = <&rpmhcc RPMH_CXO_CLK>,
			 <&gcc GCC_GPU_GPLL0_CLK_SRC>,
			 <&gcc GCC_GPU_GPLL0_DIV_CLK_SRC>;
		clock-names = "bi_tcxo",
			      "gpll0_out_main",
			      "gpll0_out_main_div";
		#clock-cells = <1>;
		#reset-cells = <1>;
		#power-domain-cells = <1>;
	};

	gxclkctl: clock-controller@3d68024 {
		compatible = "qcom,seraph-gxclkctl";
		reg = <0x3d68024 0x8>;
		reg-name = "cc_base";
		power-domains = <&gpucc GPU_CC_CX_GDSC>;
		vdd_gfx-supply = <&VDD_GFX_LEVEL>;
		#power-domain-cells = <1>;
	};

	lsrcc: clock-controller@a9f0000 {
		compatible = "qcom,seraph-lsrcc", "syscon";
		reg = <0xa9f0000 0x10000>;
		reg-name = "cc_base";
		vdd_mm-supply = <&VDD_MM_LEVEL>;
		vdd_mx-supply = <&VDD_MX_LEVEL>;
		clocks = <&rpmhcc RPMH_CXO_CLK>,
			 <&sleep_clk>, <&gcc GCC_LSR_AHB_CLK>;
		clock-names = "bi_tcxo",
			      "sleep_clk", "iface";
		#clock-cells = <1>;
		#reset-cells = <1>;
		#power-domain-cells = <1>;
	};

	tcsrcc: clock-controller@1ff1108 {
		compatible = "qcom,seraph-tcsrcc", "syscon";
		reg = <0x1ff1108 0x18>;
		reg-name = "cc_base";
		#clock-cells = <1>;
		#reset-cells = <1>;
	};

	videocc: clock-controller@aaf0000 {
		compatible = "qcom,seraph-videocc", "syscon";
		reg = <0xaaf0000 0x10000>;
		reg-name = "cc_base";
		vdd_mm-supply = <&VDD_MM_LEVEL>;
		vdd_mx-supply = <&VDD_MX_LEVEL>;
		clocks = <&rpmhcc RPMH_CXO_CLK>, <&gcc GCC_VIDEO_AHB_CLK>;
		clock-names = "bi_tcxo", "iface";
		#clock-cells = <1>;
		#reset-cells = <1>;
		#power-domain-cells = <1>;
	};

	apsscc: syscon@17aa0000 {
		compatible = "syscon";
		reg = <0x17aa0000 0x1c>;
	};

	mccc: syscon@240ba000 {
		compatible = "syscon";
		reg = <0x240ba000 0x54>;
	};

	gxclkctldebugcc: clock-controller@3d64000 {
		compatible = "syscon";
		reg = <0x3d64000 0x5000>;
	};

	debugcc: clock-controller@0 {
		compatible = "qcom,seraph-debugcc";
		qcom,apsscc = <&apsscc>;
		qcom,camcc = <&camcc>;
		qcom,evacc = <&evacc>;
		qcom,gcc = <&gcc>;
		qcom,gpucc = <&gpucc>;
		qcom,gxclkctl = <&gxclkctldebugcc>;
		qcom,lsrcc = <&lsrcc>;
		qcom,videocc = <&videocc>;
		qcom,mccc = <&mccc>;
		clocks = <&rpmhcc RPMH_CXO_CLK>, <&camcc 0>,
			 <&evacc 0>, <&gcc 0>, <&gpucc 0>,
			 <&lsrcc 0>, <&videocc 0>;
		clock-names = "xo_clk_src", "camcc",
			      "evacc", "gcc", "gpucc",
			      "lsrcc", "videocc";
		#clock-cells = <1>;
	};

	cpufreq_hw: qcom,cpufreq-hw {
		compatible = "qcom,cpufreq-epss";
		reg = <0x17d91000 0x1000>, <0x17d92000 0x1000>;
		reg-names = "freq-domain0", "freq-domain1";
		clocks = <&rpmhcc RPMH_CXO_CLK>, <&gcc GCC_GPLL0>;
		clock-names = "xo", "alternate";
		interrupts = <GIC_SPI 30 IRQ_TYPE_LEVEL_HIGH>,
			<GIC_SPI 31 IRQ_TYPE_LEVEL_HIGH>;
		interrupt-names = "dcvsh0_int", "dcvsh1_int";
		#freq-domain-cells = <1>;
	};

	qcom,cpufreq-hw-debug {
		compatible = "qcom,cpufreq-hw-epss-debug";
		qcom,freq-hw-domain = <&cpufreq_hw 0>, <&cpufreq_hw 1>;
	};

	qcom,msm-imem@14680000 {
		compatible = "qcom,msm-imem";
		reg = <0x14680000 0x1000>;
		ranges = <0x0 0x14680000 0x1000>;
		#address-cells = <1>;
		#size-cells = <1>;

		mem_dump_table@10 {
			compatible = "qcom,msm-imem-mem_dump_table";
			reg = <0x10 0x8>;
		};

		restart_reason@65c {
			compatible = "qcom,msm-imem-restart_reason";
			reg = <0x65c 0x4>;
		};

		dload_type@1c {
			compatible = "qcom,msm-imem-dload-type";
			reg = <0x1c 0x4>;
		};

		boot_stats@6b0 {
			compatible = "qcom,msm-imem-boot_stats";
			reg = <0x6b0 0x20>;
		};

		kaslr_offset@6d0 {
			compatible = "qcom,msm-imem-kaslr_offset";
			reg = <0x6d0 0xc>;
		};

		pil@94c {
			compatible = "qcom,pil-reloc-info";
			reg = <0x94c 0xc8>;
		};

		pil@6dc {
			compatible = "qcom,msm-imem-pil-disable-timeout";
			reg = <0x6dc 0x4>;
		};

		diag_dload@c8 {
			compatible = "qcom,msm-imem-diag-dload";
			reg = <0xc8 0xc8>;
		};

		modem_dsm@c98 {
			compatible = "qcom,msm-imem-mss-dsm";
			reg = <0xc98 0x10>;
		};

		sys_dbg@af8 {
			compatible = "qcom,msm-imem-gpu-dump-skip";
			reg = <0xb0c 0x4>;
		};
	};

	pdm_pwm: pdm_pwm@88f0000 {
		compatible = "qcom,pdm-pwm-v2";
		reg = <0x88f0000 0xc000>;
		clocks = <&gcc GCC_PDM_AHB_CLK>;
		clock-names =  "pdm_ahb_clk";
		assigned-clocks = <&gcc GCC_PWM0_XO512_CLK>;
		assigned-clock-rates = <19200000>;
		#pwm-cells = <3>;

		pwm@0 {
			frame-index = <0>;
			frame-offset = <0x1000>;
			clocks = <&gcc GCC_PWM0_XO512_CLK>;
			clock-names = "frame-clk";
		};

		pwm@1 {
			frame-index = <1>;
			frame-offset = <0x2000>;
			clocks = <&gcc GCC_PWM1_XO512_CLK>;
			clock-names = "frame-clk";
		};

		pwm@2 {
			frame-index = <2>;
			frame-offset = <0x3000>;
			clocks = <&gcc GCC_PWM2_XO512_CLK>;
			clock-names = "frame-clk";
		};

		pwm@3 {
			frame-index = <3>;
			frame-offset = <0x4000>;
			clocks = <&gcc GCC_PWM3_XO512_CLK>;
			clock-names = "frame-clk";
		};

		pwm@4 {
			frame-index = <4>;
			frame-offset = <0x5000>;
			clocks = <&gcc GCC_PWM4_XO512_CLK>;
			clock-names = "frame-clk";
		};

		pwm@5 {
			frame-index = <5>;
			frame-offset = <0x6000>;
			clocks = <&gcc GCC_PWM5_XO512_CLK>;
			clock-names = "frame-clk";
		};

		pwm@6 {
			frame-index = <6>;
			frame-offset = <0x7000>;
			clocks = <&gcc GCC_PWM6_XO512_CLK>;
			clock-names = "frame-clk";
		};

		pwm@7 {
			frame-index = <7>;
			frame-offset = <0x8000>;
			clocks = <&gcc GCC_PWM7_XO512_CLK>;
			clock-names = "frame-clk";
		};

		pwm@8 {
			frame-index = <8>;
			frame-offset = <0x9000>;
			clocks = <&gcc GCC_PWM8_XO512_CLK>;
			clock-names = "frame-clk";
		};

		pwm@9 {
			frame-index = <9>;
			frame-offset = <0xa000>;
			clocks = <&gcc GCC_PWM9_XO512_CLK>;
			clock-names = "frame-clk";
		};
	};

	dcp_cb_group: dcp_cb_group {
		qcom,iommu-faults = "non-fatal";
	};

	qcom,msm-adsprpc-mem {
		compatible = "qcom,msm-adsprpc-mem-region";
		memory-region = <&adsp_mem_heap>;
	};

	qcom,sps {
		compatible = "qcom,msm-sps-v1_7-4k";
		qcom,pipe-attr-ee;
	};

	sdhc1_opp_table: sdhc1-opp-table {
		compatible = "operating-points-v2";

		opp-100000000 {
			opp-hz = /bits/ 64 <100000000>;
			opp-peak-kBps = <250000 133320>;
			opp-avg-kBps = <104000 0>;
		};

		opp-384000000 {
			opp-hz = /bits/ 64 <384000000>;
			opp-peak-kBps = <1900000 300000>;
			opp-avg-kBps = <400000 0>;
		};
	};

	qcom_tzlog: tz-log@14680720 {
		compatible = "qcom,tz-log";
		reg = <0x14680720 0x3000>;
		qcom,hyplog-enabled;
		hyplog-address-offset = <0x410>;
		hyplog-size-offset = <0x414>;
		tmecrashdump-address-offset = <0x81CA0000>;
	};

	qcom_cedev: qcedev@1de0000 {
		compatible = "qcom,qcedev";
		reg = <0x1de0000 0x20000>,
				<0x1dc4000 0x28000>;
		reg-names = "crypto-base","crypto-bam-base";
		interrupts = <GIC_SPI 272 IRQ_TYPE_LEVEL_HIGH>,
				<GIC_SPI 274 IRQ_TYPE_EDGE_RISING>;
		interrupt-names = "bam-irq", "core-irq";
		qcom,bam-pipe-pair = <2>;
		qcom,offload-ops-support;
		qcom,bam-pipe-offload-cpb-hlos = <1>;
		qcom,bam-pipe-offload-hlos-cpb = <3>;
		qcom,bam-pipe-offload-hlos-cpb-1 = <8>;
		qcom,bam-pipe-offload-hlos-hlos = <4>;
		qcom,bam-pipe-offload-hlos-hlos-1 = <9>;
		qcom,ce-hw-instance = <0>;
		qcom,ce-device = <0>;
		qcom,ce-hw-shared;
		qcom,bam-ee = <0>;
		qcom,smmu-s1-enable;
		qcom,no-clock-support;
		qcom,no-clk-gating;
		interconnect-names = "data_path";
		interconnects = <&system_noc MASTER_CRYPTO &mc_virt SLAVE_EBI1>;
		iommus = <&apps_smmu 0x080 0x0>,
				<&apps_smmu 0x081 0x0>;
		qcom,iommu-dma = "atomic";
		dma-coherent;

		qcom_cedev_ns_cb {
			compatible = "qcom,qcedev,context-bank";
			label = "ns_context";
			iommus = <&apps_smmu 0x081 0x0>;
			dma-coherent;
		};

		qcom_cedev_s_cb {
			compatible = "qcom,qcedev,context-bank";
			label = "secure_context";
			iommus = <&apps_smmu 0x083 0x0>;
			qcom,iommu-vmid = <0x9>;
			qcom,secure-context-bank;
			dma-coherent;
		};
	};

	qcom_rng: qrng@10c3000 {
		compatible = "qcom,msm-rng";
		reg = <0x10c3000 0x1000>;
		qcom,no-qrng-config;
		qcom,no-clock-support;
	};

	sdhc_1_dma_resv: sdhc_1_dma_resv_region {
		/*
		 * Restrict IOVA mappings for SDHC1 buffers to the 256 MB region
		 * from 0x40000000 - 0x4fffffff.
		 */
		iommu-addresses = <&sdhc_1 0x0 0x40000000>,
				<&sdhc_1 0x50000000 0xb0000000>;
	};

	sdhc_1: sdhci@B24000 {
		status = "disabled";

		compatible = "qcom,sdhci-msm-v5";
		#address-cells = <1>;
		#size-cells = <1>;

		reg = <0xB24000 0x1000>, <0xB25000 0x1000>, <0xB28000 0x18000>;
		reg-names = "hc", "cqhci", "ice";

		iommus = <&apps_smmu 0x120 0x0>;
		dma-coherent;
		qcom,iommu-dma = "fastmap";

		qcom,ice-use-hwkm;
		/*
		 * iommu-addresses - Indicate the range of data addresses which will NOT
		 * be used in dma allocation.
		 *
		 * iommu-geometry -  This is specific for fastmap which Allow clients
		 * to save SMMU page table memory.
		 *
		 * The 2nd parameter indicates size of the smmu page table memory.
		 * If its exceeds beyond this size, last unused entry from page table
		 * memory will be invalidated.
		 *
		 * It's better to provide range of dma address, hence provide
		 * iommu-dma-addr-pool property along with iommu-geometry property.
		 */

		memory-region = <&sdhc_1_dma_resv>;
		qcom,iommu-geometry = <0x40000000 0x10000000>;

		interrupts = <GIC_SPI 150 IRQ_TYPE_LEVEL_HIGH>,
				<GIC_SPI 261 IRQ_TYPE_LEVEL_HIGH>;
		interrupt-names = "hc_irq", "pwr_irq";

		clocks = <&gcc GCC_SDCC1_APPS_CLK>,
			<&gcc GCC_SDCC1_AHB_CLK>,
			<&gcc GCC_SDCC1_ICE_CORE_CLK>;
		clock-names = "core", "iface", "ice_core";

		qcom,ice-clk-rates = <300000000 100000000>;

		interconnects = <&system_noc MASTER_SDCC_1 &mc_virt SLAVE_EBI1>,
			<&gem_noc MASTER_APPSS_PROC &cnoc_cfg SLAVE_SDCC_1>;
		interconnect-names = "sdhc-ddr","cpu-sdhc";
		operating-points-v2 = <&sdhc1_opp_table>;

	      /* DLL HSR settings. Refer go/hsr - <Target> DLL settings */
		qcom,dll-hsr-list = <0x000F44EC 0x0 0x01 0x290106C0 0x80040868>;

		cap-mmc-hw-reset;
		qcom,restore-after-cx-collapse;

		non-removable;
		supports-cqe;

		no-sd;
		no-sdio;

		bus-width = <8>;

		resets = <&gcc GCC_SDCC1_BCR>;
		reset-names = "core_reset";

		qos0 {
			mask = <0x10>;
			vote = <44>;
		};

		qos1 {
			mask = <0x0f>;
			vote = <44>;
		};
	};

	qcom,power-state {
		compatible = "qcom,power-state";
		qcom,subsys-name = "cdsp", "lpass", "soccp";
		qcom,rproc-handle = <&cdsp_pas>, <&adsp_pas>, <&soccp_pas>;
	};

	tlmm: pinctrl@f000000 {
		compatible = "qcom,seraph-pinctrl";
		reg = <0xF000000 0x1000000>;
		interrupts = <GIC_SPI 208 IRQ_TYPE_LEVEL_HIGH>;
		gpio-controller;
		#gpio-cells = <2>;
		interrupt-controller;
		#interrupt-cells = <2>;
		wakeup-parent = <&pdc>;
		qcom,gpios-reserved = <18 19>;
	};

	pcie_crm_hw_0_bcm_voter: bcm_voter@0 {
		compatible = "qcom,bcm-voter";
		qcom,crm-name = "pcie_crm";
		qcom,crm-client-idx = <0>;
		qcom,crm-pwr-states = <5>;
	};

	pcie_crm_hw_1_bcm_voter: bcm_voter@1 {
		compatible = "qcom,bcm-voter";
		qcom,crm-name = "pcie_crm";
		qcom,crm-client-idx = <1>;
		qcom,crm-pwr-states = <5>;
	};

	clk_virt: interconnect@0 {
		compatible = "qcom,seraph-clk_virt";
		#interconnect-cells = <1>;
		qcom,bcm-voter-names = "hlos", "pcie_crm_hw_0", "pcie_crm_hw_1";
		qcom,bcm-voters = <&apps_bcm_voter>,
				  <&pcie_crm_hw_0_bcm_voter>,
				  <&pcie_crm_hw_1_bcm_voter>;
	};

	mc_virt: interconnect@1 {
		compatible = "qcom,seraph-mc_virt";
		#interconnect-cells = <1>;
		qcom,bcm-voter-names = "hlos", "pcie_crm_hw_0", "pcie_crm_hw_1";
		qcom,bcm-voters = <&apps_bcm_voter>,
				  <&pcie_crm_hw_0_bcm_voter>,
				  <&pcie_crm_hw_1_bcm_voter>;
	};

	cnoc_cfg: interconnect@1600000 {
		compatible = "qcom,seraph-config_noc_cfg";
		reg = <0x01600000 0x7200>;
		#interconnect-cells = <1>;
		qcom,bcm-voter-names = "hlos";
		qcom,bcm-voters = <&apps_bcm_voter>;
	};

	cnoc_main: interconnect@1500000 {
		compatible = "qcom,seraph-config_noc_main";
		reg = <0x01500000 0x1a200>;
		#interconnect-cells = <1>;
		qcom,bcm-voter-names = "hlos";
		qcom,bcm-voters = <&apps_bcm_voter>;
	};

	gem_noc: interconnect@24100000 {
		compatible = "qcom,seraph-gem_noc";
		reg = <0x24100000 0x163080>;
		#interconnect-cells = <1>;
		qcom,bcm-voter-names = "hlos", "pcie_crm_hw_0", "pcie_crm_hw_1";
		qcom,bcm-voters = <&apps_bcm_voter>,
				  <&pcie_crm_hw_0_bcm_voter>,
				  <&pcie_crm_hw_1_bcm_voter>;
	};

	lpass_ag_noc: interconnect@8240000 {
		compatible = "qcom,seraph-lpass_ag_noc";
		reg = <0x08240000 0xe080>;
		#interconnect-cells = <1>;
		qcom,bcm-voter-names = "hlos";
		qcom,bcm-voters = <&apps_bcm_voter>;
	};

	lpass_lpiaon_noc: interconnect@07800000 {
		compatible = "qcom,seraph-lpass_lpiaon_noc";
		reg = <0x07800000 0x19080>;
		#interconnect-cells = <1>;
		qcom,bcm-voter-names = "hlos";
		qcom,bcm-voters = <&apps_bcm_voter>;
	};

	lpass_lpicx_noc: interconnect@07820000 {
		compatible = "qcom,seraph-lpass_lpicx_noc";
		reg = <0x07820000 0x44080>;
		#interconnect-cells = <1>;
		qcom,bcm-voter-names = "hlos";
		qcom,bcm-voters = <&apps_bcm_voter>;
	};

	mmss_noc: interconnect@1780000 {
		compatible = "qcom,seraph-mmss_noc";
		reg = <0x01780000 0x6b800>;
		#interconnect-cells = <1>;
		qcom,bcm-voter-names = "hlos";
		qcom,bcm-voters = <&apps_bcm_voter>;
	};

	nsp_noc: interconnect@320C0000 {
		compatible = "qcom,seraph-nsp_noc";
		reg = <0x320C0000 0x1f400>;
		#interconnect-cells = <1>;
		qcom,bcm-voter-names = "hlos";
		qcom,bcm-voters = <&apps_bcm_voter>;
	};

	pcie_anoc: interconnect@16C0000 {
		compatible = "qcom,seraph-pcie_anoc";
		reg = <0x016C0000 0xe400>;
		#interconnect-cells = <1>;
		qcom,bcm-voter-names = "hlos", "pcie_crm_hw_0", "pcie_crm_hw_1";
		qcom,bcm-voters = <&apps_bcm_voter>,
				  <&pcie_crm_hw_0_bcm_voter>,
				  <&pcie_crm_hw_1_bcm_voter>;
		clocks = <&gcc GCC_AGGRE_NOC_PCIE_AXI_CLK>,
			 <&gcc GCC_CFG_NOC_PCIE_ANOC_AHB_CLK>;
	};

	system_noc: interconnect@1680000 {
		compatible = "qcom,seraph-system_noc";
		reg = <0x01680000 0x2d800>;
		#interconnect-cells = <1>;
		qcom,bcm-voter-names = "hlos";
		qcom,bcm-voters = <&apps_bcm_voter>;
		clocks = <&gcc GCC_AGGRE_USB3_PRIM_AXI_CLK>,
			 <&gcc GCC_SDCC1_AHB_CLK>,
			 <&gcc GCC_SDCC2_AHB_CLK>,
			 <&rpmhcc RPMH_IPA_CLK>;
	};

	cache-controller@25000000 {
		compatible = "qcom,seraph-llcc";
		reg = <0x25000000 0x200000> , <0x25400000 0x200000>, <0x25800000 0x200000>, <0x25A00000 0x200000>, <0xD8170000 0x1000>;
		reg-names = "llcc0_base", "llcc1_base", "llcc_broadcast_or_base", "llcc_broadcast_and_base", "slc_mem_base";
		interrupts = <GIC_SPI 266 IRQ_TYPE_LEVEL_HIGH>;
		memory-region = <&sc_tcm_mem>;
		cap-based-alloc-and-pwr-collapse;
		qcom,sct-initialized;
		ranges;

		llcc-perfmon {
			compatible = "qcom,llcc-perfmon";
			clocks = <&aoss_qmp QDSS_CLK>;
			clock-names = "qdss_clk";
			llcc-scid-status-snapshot;
		};

		slc_perfmon: qcom,slc_perfmon {
			compatible = "qcom,slc-perfmon";
			/* Dedicated perfmon shared mem region, perfmon struct at offset 0x0 */
			reg = <0xd8171000 0x1000>, <0x25000000 0x60000>, <0x25400000 0x60000>, <0x25800000 0x60000>;
			reg-names = "perfmon_base", "trp_0_base", "trp_1_base", "trp_or_bcast_base";
			perfmon_offset = <0x0>;
			clocks = <&aoss_qmp QDSS_CLK>;
			clock-names = "qdss_clk";
			slc-scid-status-snapshot;
		};
	};

	qcom,msm_gsi {
		compatible = "qcom,msm_gsi";
	};

	ipa_hw: qcom,ipa@3e00000 {
		compatible = "qcom,ipa";
		reg =
			<0x3e00000 0x84000>,
			<0x3e04000 0xfc000>;
		reg-names = "ipa-base", "gsi-base";
		qcom,ipa-cfg-offset = <0x0140000>;
		interrupts =
			<0 654 IRQ_TYPE_LEVEL_HIGH>,
			<0 432 IRQ_TYPE_LEVEL_HIGH>;
		interrupt-names = "ipa-irq", "gsi-irq";
		qcom,ipa-hw-ver = <24>; /* IPA core version = IPAv5.5 */
		qcom,ipa-hw-mode = <0>;
		qcom,use-xbl-boot; /* Using XBL to load IPA_FW */
		qcom,platform-type = <3>; /* XR platform */
		qcom,ee = <0>;
		qcom,entire-ipa-block-size = <0x200000>;
		qcom,use-ipa-tethering-bridge;
		qcom,ipa-wdi3-over-gsi;
		qcom,arm-smmu;
		qcom,smmu-fast-map;
		qcom,use-64-bit-dma-mask;
		qcom,ipa-endp-delay-wa-v2;
		qcom,lan-rx-napi;
		qcom,tx-napi;
		qcom,tx-poll;
		qcom,register-collection-on-crash;
		qcom,testbus-collection-on-crash;
		qcom,non-tn-collection-on-crash;
		qcom,tx-wrapper-cache-max-size = <400>;
		qcom,ipa-gpi-event-rp-ddr;
		qcom,max_num_smmu_cb = <2>;
		clock-names = "core_clk";
		clocks = <&rpmhcc RPMH_IPA_CLK>;
		qcom,throughput-threshold = <2000 4000 8000>;
		qcom,ipa-wdi-opt-dpath;
		qcom,scaling-exceptions = <>;
		qcom,interconnect,num-cases = <5>;
		qcom,interconnect,num-paths = <3>;
		qcom,qmp = <&aoss_qmp>;
		interconnects = <&system_noc MASTER_IPA &gem_noc SLAVE_LLCC>,
		<&mc_virt MASTER_LLCC &mc_virt SLAVE_EBI1>,
		<&gem_noc MASTER_APPSS_PROC &cnoc_main SLAVE_IPA_CFG>;
		interconnect-names = "ipa_to_llcc", "llcc_to_ebi1", "appss_to_ipa";

		/* No vote */
		qcom,no-vote =
		<0 0 0 0 0 0>;

		/* SVS2 */
		qcom,svs2 =
		<0 0 0 1300000 0 76800>;

		/* SVS */
		qcom,svs =
		<1200000 0 1200000 2800000 0 150000>;

		/* NOMINAL */
		qcom,nominal =
		<2400000 0 2400000 5500000 0 400000>;

		/* TURBO */
		qcom,turbo =
		<3600000 0 3600000 5500000 0 400000>;

		qcom,bus-vector-names = "MIN", "SVS2", "SVS", "NOMINAL",
			"TURBO";

		#address-cells=<2>;
		#size-cells=<2>;

		ipa_smmu_ap_partition: ipa_smmu_ap_partition {
			iommu-addresses = <&ipa_smmu_ap 0x0 0x0 0x0 0x20000000>,
				<&ipa_smmu_ap 0x0 0x40000000 0xFFFFFFFF 0xC0000000>;
		};

		ipa_smmu_uc_partition: ipa_smmu_uc_partition {
			iommu-addresses = <&ipa_smmu_uc 0x0 0x0 0x0 0x20000000>,
				<&ipa_smmu_uc 0x0 0x40000000 0xFFFFFFFF 0xC0000000>;
		};

		ipa_smmu_ap: ipa_smmu_ap {
			compatible = "qcom,ipa-smmu-ap-cb";
			iommus = <&apps_smmu 0x0A0 0x0>;
			qcom,ipa-dma-addr-pool = <0x20000000 0x20000000>;
			memory-region = <&ipa_smmu_ap_partition>;
			qcom,additional-mapping =
				/* modem tables in IMEM */
				<0x14683000 0x14683000 0x2000>;
			qcom,iommu-dma = "atomic";
			qcom,ipa-q6-smem-size = <45056>;
			dma-coherent;
		};

		ipa_smmu_uc: ipa_smmu_uc {
			compatible = "qcom,ipa-smmu-uc-cb";
			iommus = <&apps_smmu 0x0A2 0x0>;
			qcom,ipa-dma-addr-pool = <0x20000000 0x20000000>;
			memory-region = <&ipa_smmu_uc_partition>;
			/* Map IPCC Fence Protocol Region to uC CB */
			qcom,ipcc-mapping = <0x504000 0x504000 0x1000>;
			qcom,iommu-dma = "atomic";
			dma-coherent;
		};
	};

	qcom,mem-buf {
		compatible = "qcom,mem-buf";
		qcom,mem-buf-capabilities = "supplier";
		qcom,vmid = <3>;
	};

	qcom_smcinvoke {
		compatible = "qcom,smcinvoke";
	};

	qcom_mem_object {
		compatible = "qcom,mem-object";
	};

	qtee_shmbridge {
		compatible = "qcom,tee-shared-memory-bridge";
	};

	qcom,mem-buf-msgq {
		compatible = "qcom,mem-buf-msgq";
		qcom,msgq-names = "trusted_vm";
	};

	qcom,test-large-dmabuf-tuivm {
		compatible = "qcom,gh-large-dmabuf-test";
		gunyah-label = <0x10d>;
		qcom,primary;
	};

	qcom,secure-buffer {
		compatible = "qcom,secure-buffer";
		qcom,vmid-cp-camera-preview-ro;
	};

	tlmm-vm-mem-access {
		compatible = "qcom,tlmm-vm-mem-access";
		qcom,master;

		tuivm {
			qcom,label = <0x08>;
			qcom,vmid = <45>;
			tlmm-vm-gpio-list = <&tlmm 12 0>;
		};
	};

	tlmm-vm-test {
		compatible = "qcom,tlmm-vm-test";
		qcom,master;
		tlmm-vm-gpio-list = <&tlmm 12 0>;
	};

	qcom,gunyah-panic-notifier {
		compatible = "qcom,gh-panic-notifier";
		qcom,primary-vm;
		gunyah-label = <0x109>;
		peer-name = <2>;
		memory-region = <&vm_comm_mem>;
		shared-buffer-size = <0x1000>;
	};

	dmesg-dump {
		compatible = "qcom,dmesg-dump";
		qcom,primary-vm;
		gunyah-label = <0x107>;
		peer-name = <2>;
		memory-region = <&vm_comm_mem>;
		shared-buffer-size = <0x1000>;
	};

	gunyah-cma-mem {
		compatible = "gunyah-cma-vm-mem";
		memory-region = <&trust_ui_vm_mem>;
		memory-region-names = "trustedvm_cma";
	};

	mini_dump_mode {
		compatible = "qcom,minidump";
	};

	va_mini_dump {
		compatible = "qcom,va-minidump";
		memory-region = <&va_md_mem>;
	};

	thermal_zones: thermal-zones {};

	spmi_bus: spmi0_bus: qcom,spmi@c42d000 {
		compatible = "qcom,spmi-pmic-arb";
		reg = <0xc42d000 0x4000>,
		      <0xc400000 0x3000>,
		      <0xc500000 0x400000>,
		      <0xc440000 0x80000>,
		      <0xc4c0000 0x10000>;
		reg-names = "cnfg", "core", "chnls", "obsrvr", "intr";
		interrupts-extended = <&pdc 1 IRQ_TYPE_LEVEL_HIGH>;
		interrupt-names = "periph_irq";
		interrupt-controller;
		#interrupt-cells = <4>;
		#address-cells = <2>;
		#size-cells = <0>;
		cell-index = <0>;
		qcom,channel = <0>;
		qcom,ee = <0>;
		qcom,bus-id = <0>;
	};

	spmi0_debug_bus: qcom,spmi-debug@11314000 {
		compatible = "qcom,spmi-pmic-arb-debug";
		reg = <0x11314000 0x60>, <0x221c8784 0x4>;
		reg-names = "core", "fuse";
		clocks = <&aoss_qmp>;
		clock-names = "core_clk";
		qcom,fuse-enable-bit = <18>;
		#address-cells = <2>;
		#size-cells = <0>;
		depends-on-supply = <&spmi0_bus>;

		qcom,pmar2230-debug@0 {
			compatible = "qcom,spmi-pmic";
			reg = <0 SPMI_USID>;
			#address-cells = <2>;
			#size-cells = <0>;
			qcom,can-sleep;
		};

		qcom,pmg1110-debug@a {
			compatible = "qcom,spmi-pmic";
			reg = <10 SPMI_USID>;
			#address-cells = <2>;
			#size-cells = <0>;
			qcom,can-sleep;
		};

		qcom,pm8010-debug@c {
			compatible = "qcom,spmi-pmic";
			reg = <12 SPMI_USID>;
			#address-cells = <2>;
			#size-cells = <0>;
			qcom,can-sleep;
		};

		qcom,pm8010-debug@d {
			compatible = "qcom,spmi-pmic";
			reg = <13 SPMI_USID>;
			#address-cells = <2>;
			#size-cells = <0>;
			qcom,can-sleep;
		};
	};

	adsp_pas: remoteproc-adsp@06C00000 {
		compatible = "qcom,seraph-adsp-pas";
		reg = <0x06C00000 0x10000>;
		status = "ok";

		cx-supply = <&VDD_LPI_CX_LEVEL>;
		cx-uV-uA = <RPMH_REGULATOR_LEVEL_TURBO 0>;
		mx-supply = <&VDD_LPI_MX_LEVEL>;
		mx-uV-uA = <RPMH_REGULATOR_LEVEL_TURBO 0>;
		reg-names = "cx", "mx";

		clocks = <&rpmhcc RPMH_CXO_CLK>;
		clock-names = "xo";

		qcom,signal-aop;
		qcom,qmp = <&aoss_qmp>;

		interconnects = <&lpass_lpicx_noc MASTER_LPASS_PROC &mc_virt SLAVE_EBI1>,
				<&system_noc MASTER_CRYPTO &mc_virt SLAVE_EBI1>;

		interconnect-names = "rproc_ddr", "crypto_ddr";

		memory-region = <&adsp_mem &q6_adsp_dtb_mem>;
		/* Inputs from ssc */
		interrupts-extended = <&pdc 6 IRQ_TYPE_EDGE_RISING>,
					<&adsp_smp2p_in 0 0>,
					<&adsp_smp2p_in 2 0>,
					<&adsp_smp2p_in 1 0>,
					<&adsp_smp2p_in 3 0>,
					<&adsp_smp2p_in 7 0>;

		interrupt-names = "wdog",
				"fatal",
				"handover",
				"ready",
				"stop-ack",
				"shutdown-ack";

		/* Outputs to turing */
		qcom,smem-states = <&adsp_smp2p_out 0>;
		qcom,smem-state-names = "stop";

		remoteproc_adsp_glink: glink-edge {
			qcom,remote-pid = <2>;
			transport = "smem";
			mboxes = <&ipcc_mproc IPCC_CLIENT_LPASS
				  IPCC_MPROC_SIGNAL_GLINK_QMP>;
			mbox-names = "adsp_smem";
			interrupt-parent = <&ipcc_mproc>;
			interrupts = <IPCC_CLIENT_LPASS
				      IPCC_MPROC_SIGNAL_GLINK_QMP
				      IRQ_TYPE_EDGE_RISING>;

			label = "adsp";
			qcom,glink-label = "lpass";

			qcom,adsp_qrtr {
				qcom,glink-channels = "IPCRTR";
				qcom,net-id = <2>;
				qcom,intents = <0x800  5
						0x2000 3
						0x4400 2>;

				qcom,no-wake-svc = <0x190>;
			};

			qcom,pmic_glink_rpmsg {
				qcom,glink-channels = "PMIC_RTR_ADSP_APPS";
			};

			qcom,pmic_glink_log_rpmsg {
				qcom,glink-channels = "PMIC_LOGS_ADSP_APPS";
				qcom,intents = <0x800 5
						0xc00 3
						0x2000 1>;
			};
		};
	};

	cdsp_pas: remoteproc-cdsp@32300000 {
		compatible = "qcom,seraph-cdsp-pas";
		reg = <0x32300000 0x10000>;
		status = "ok";
		cx-supply = <&VDD_CX_LEVEL>;
		cx-uV-uA = <RPMH_REGULATOR_LEVEL_TURBO 100000>;
		mx-supply = <&VDD_MX_LEVEL>;
		mx-uV-uA = <RPMH_REGULATOR_LEVEL_TURBO 100000>;
		nsp-supply = <&VDD_NSP_LEVEL>;
		nsp-uV-uA = <RPMH_REGULATOR_LEVEL_TURBO 100000>;
		reg-names = "cx","mx","nsp";

		firmware-name = "cdsp.mdt", "cdsp_dtb.mdt";
		memory-region = <&cdsp_mem &q6_cdsp_dtb_mem>;
		global-sync-mem-reg = <&global_sync_mem>;

		clocks = <&rpmhcc RPMH_CXO_CLK>;
		clock-names = "xo";

		qcom,signal-aop;
		qcom,qmp = <&aoss_qmp>;

		interconnects = <&nsp_noc MASTER_CDSP_PROC &mc_virt SLAVE_EBI1>,
				<&system_noc MASTER_CRYPTO &mc_virt SLAVE_EBI1>;

		interconnect-names = "rproc_ddr", "crypto_ddr";

		/* Inputs from turing */
		interrupts-extended = <&intc GIC_SPI 578 IRQ_TYPE_EDGE_RISING>,
					<&cdsp_smp2p_in 0 0>,
					<&cdsp_smp2p_in 2 0>,
					<&cdsp_smp2p_in 1 0>,
					<&cdsp_smp2p_in 3 0>;

		interrupt-names = "wdog",
				"fatal",
				"handover",
				"ready",
				"stop-ack";

		/* Outputs to turing */
		qcom,smem-states = <&cdsp_smp2p_out 0>;
		qcom,smem-state-names = "stop";

		remoteproc_cdsp_glink: glink-edge {
			qcom,remote-pid = <5>;
			transport = "smem";
			mboxes = <&ipcc_mproc IPCC_CLIENT_CDSP
				  IPCC_MPROC_SIGNAL_GLINK_QMP>;
			mbox-names = "cdsp_smem";
			interrupt-parent = <&ipcc_mproc>;
			interrupts = <IPCC_CLIENT_CDSP
				      IPCC_MPROC_SIGNAL_GLINK_QMP
				      IRQ_TYPE_EDGE_RISING>;

			label = "cdsp";
			qcom,glink-label = "cdsp";

			qcom,cdsp_qrtr {
				qcom,glink-channels = "IPCRTR";
				qcom,intents = <0x800  5
						0x2000 3
						0x4400 2>;
			};
		};
	};

	soccp_pas: remoteproc-soccp@a1f80000 {
		compatible = "qcom,seraph-soccp-pas";
		reg = <0xa1f80000 0x10000>;
		status = "ok";

		cx-supply = <&VDD_CX_LEVEL>;
		cx-uV-uA = <RPMH_REGULATOR_LEVEL_LOW_SVS 0>;
		mx-supply = <&VDD_MXA_LEVEL>;
		mx-uV-uA = <RPMH_REGULATOR_LEVEL_LOW_SVS 0>;
		reg-names = "cx", "mx";

		clocks = <&rpmhcc RPMH_CXO_CLK>;
		clock-names = "xo";

		interconnects = <&system_noc MASTER_SOCCP_AGGR_NOC &mc_virt SLAVE_EBI1>,
				<&gem_noc MASTER_APPSS_PROC &cnoc_main SLAVE_SOCCP>;
		interconnect-names = "rproc_ddr", "rproc_cnoc";

		firmware-name = "soccp.mbn", "soccp_dtb.mbn";

		memory-region = <&soccp_mem &soccp_dtb_mem>;

		/* Inputs from SOCCP */
		interrupts-extended = <&intc GIC_SPI 256 IRQ_TYPE_EDGE_RISING>,
					<&soccp_smp2p_in 0 0>,
					<&soccp_smp2p_in 1 0>,
					<&soccp_smp2p_in 3 0>,
					<&soccp_smp2p_in 2 0>,
					<&soccp_smp2p_in 9 0>,
					<&soccp_smp2p_in 10 0>;

		interrupt-names = "wdog",
				"fatal",
				"ready",
				"stop-ack",
				"handover",
				"pong",
				"wake-ack";

		/* Outputs to soccp */
		qcom,smem-states = <&soccp_smp2p_out 0>, <&soccp_smp2p_out 10>, <&soccp_smp2p_out 9>, <&soccp_smp2p_out 8>;
		qcom,smem-state-names = "stop", "wakeup", "sleep", "ping";

		glink-edge {
			qcom,remote-pid = <19>;
			transport = "smem";
			mboxes = <&ipcc_mproc IPCC_CLIENT_SOCCP
				  IPCC_MPROC_SIGNAL_GLINK_QMP>;
			mbox-names = "soccp_smem";
			interrupt-parent = <&ipcc_mproc>;
			interrupts = <IPCC_CLIENT_SOCCP
				      IPCC_MPROC_SIGNAL_GLINK_QMP
				      IRQ_TYPE_EDGE_RISING>;

			label = "soccp";
			qcom,glink-label = "soccp";

			qcom,soccp_qrtr {
				qcom,glink-channels = "IPCRTR";
				qcom,intents = <0x800  5
						0x2000 3
						0x4400 2>;
			};
		};
	};

	wdog: qcom,wdt@17410000 {
		compatible = "qcom,msm-watchdog";
		reg = <0x17410000 0x1000>;
		reg-names = "wdt-base";
		interrupts = <GIC_SPI 0 IRQ_TYPE_LEVEL_HIGH>,
			     <GIC_SPI 1 IRQ_TYPE_LEVEL_HIGH>;
		status = "ok";
	};

	psci {
		compatible = "arm,psci-1.0";
		method = "smc";
	};

	logbuf: qcom,logbuf-vendor-hooks {
		compatible = "qcom,logbuf-vendor-hooks";
	};

	google,debug-kinfo {
		compatible = "google,debug-kinfo";
		memory-region = <&kinfo_mem>;
	};

	eud: qcom,msm-eud@88e0000 {
		compatible = "qcom,msm-eud";
		interrupt-names = "eud_irq";
		interrupt-parent = <&pdc>;
		interrupts = <11 IRQ_TYPE_LEVEL_HIGH>;
		reg = <0x088e0000 0x2000>,
			<0x088e2000 0x1000>;
		reg-names = "eud_base", "eud_mode_mgr2";
		qcom,secure-eud-en;
		status = "ok";
	};

	qfprom: qfprom@221c8000 {
		compatible = "qcom,seraph-qfprom", "qcom,qfprom";
		reg = <0x221c8000 0x1000>;
		#address-cells = <1>;
		#size-cells = <1>;
		read-only;
		ranges;
	};

	qfprom_sys: qfprom@0 {
		compatible = "qcom,qfprom-sys";
	};

	qcom_ramoops {
		compatible = "qcom,ramoops";
		memory-region = <&ramoops_mem>;
		pmsg-size = <0x200000>;
		mem-type = <2>;
	};

	qcom,mpm2-sleep-counter@c221000 {
		compatible = "qcom,mpm2-sleep-counter";
		reg = <0xc221000 0x1000>;
		clock-frequency = <32768>;
	};

	gic-interrupt-router {
		compatible = "qcom,gic-intr-routing";
		qcom,gic-class0-cpus = <&CPU0 &CPU1 &CPU2 &CPU3>;
		qcom,gic-class1-cpus = <&CPU4>;
	};

	cpu_pmu: cpu-pmu {
		compatible = "arm,armv8-pmuv3";
		interrupts = <GIC_PPI 7 IRQ_TYPE_LEVEL_HIGH>;
	};

	vendor_hooks: qcom,cpu-vendor-hooks {
		compatible = "qcom,cpu-vendor-hooks";
	};

	qcom,chd {
		compatible = "qcom,core-hang-detect";
		label = "core";
		qcom,chd-percpu-info = <&CPU0 0x17800058 0x17800060>,
					<&CPU1 0x17810058 0x17810060>,
					<&CPU2 0x17820058 0x17820060>,
					<&CPU3 0x17830058 0x17830060>,
					<&CPU4 0x17840058 0x17840060>;
	};

};

&firmware {
	qcom_scm {
		compatible = "qcom,scm";
		qcom,dload-mode = <&tcsr 0x99000>;
	};

	qcom,hdcp {
		compatible = "qcom,hdcp";
		qcom,use-smcinvoke = <1>;
	};
};

&reserved_memory {
	#address-cells = <2>;
	#size-cells = <2>;
	ranges;

	/* global autoconfigured region for contiguous allocations */
	system_cma: linux,cma {
		compatible = "shared-dma-pool";
		alloc-ranges = <0x0 0x00000000 0x0 0xffffffff>;
		reusable;
		alignment = <0x0 0x400000>;
		size = <0x0 0x2000000>;
		linux,cma-default;
	};

	adsp_mem_heap: adsp_heap_region {
		compatible = "shared-dma-pool";
		alloc-ranges = <0x0 0x00000000 0x0 0xffffffff>;
		reusable;
		alignment = <0x0 0x400000>;
		size = <0x0 0xC00000>;
	};

	/* cdsp eva shared memory */
	cdsp_eva_mem: cdsp_eva_region {
		compatible = "shared-dma-pool";
		alloc-ranges = <0x0 0x00000000 0x0 0xffffffff>;
		reusable;
		alignment = <0x0 0x400000>;
		size = <0x0 0x400000>;
	};

	vm_comm_mem: vm_comm_mem_region {
		compatible = "shared-dma-pool";
		alloc-ranges = <0x0 0x00000000 0x0 0xffffffff>;
		reusable;
		alignment = <0x0 0x400000>;
		size = <0x0 0x400000>;
	};

	non_secure_display_memory: non_secure_display_region {
		compatible = "shared-dma-pool";
		alloc-ranges = <0x0 0x00000000 0x0 0xffffffff>;
		reusable;
		alignment = <0x0 0x400000>;
		size = <0x0 0xa400000>;
	};

	qseecom_mem: qseecom_region {
		compatible = "shared-dma-pool";
		alloc-ranges = <0x0 0x00000000 0x0 0xffffffff>;
		reusable;
		alignment = <0x0 0x400000>;
		size = <0x0 0x1400000>;
	};

	qseecom_ta_mem: qseecom_ta_region {
		compatible = "shared-dma-pool";
		alloc-ranges = <0x0 0x00000000 0x0 0xffffffff>;
		reusable;
		alignment = <0x0 0x400000>;
		size = <0x0 0x1000000>;
	};

	kinfo_mem: debug_kinfo_region {
		alloc-ranges = <0x0 0x00000000 0xffffffff 0xffffffff>;
		size = <0x0 0x1000>;
		no-map;
	};

	ramoops_mem: ramoops_region {
		alloc-ranges = <0x1 0x00000000 0xfffffffe 0xffffffff>;
		size = <0x0 0x200000>;
		reusable;
	};

	va_md_mem: va_md_mem_region {
		compatible = "shared-dma-pool";
		alloc-ranges = <0x0 0x00000000 0x0 0xffffffff>;
		reusable;
		size = <0 0x1000000>;
	};
};

#include "seraph-reserved-memory.dtsi"
#include "seraph-coresight.dtsi"
#include "seraph-debug.dtsi"
#include "msm-arm-smmu-seraph.dtsi"
#include "seraph-dma-heaps.dtsi"
#include "seraph-regulators.dtsi"
#include "seraph-pinctrl.dtsi"
#include "seraph-qupv3.dtsi"
#include "seraph-pcie.dtsi"
#include "ipcc-test-seraph.dtsi"
#include "msm-rdbg.dtsi"
#include "seraph-walt.dtsi"

&qupv3_se11_2uart {
	status = "ok";
};

#include "seraph-usb.dtsi"

&qupv3_se8_i2c {
	status = "ok";

	#address-cells = <1>;
	#size-cells = <0>;

	nxp_eusb2_repeater: eusb2_repeater@4f {
		compatible = "nxp,eusb2-repeater";
		reg = <0x4f>;
		vdd1v8-supply = <&pmar2230_l3>;
		vdd3v3-supply = <&pmar2230_l14>;
	};
};

&eusb2_phy0 {
	dummy-supply = <&nxp_eusb2_repeater>;
	usb-repeater = <&nxp_eusb2_repeater>;
};

#include "seraph-thermal.dtsi"
